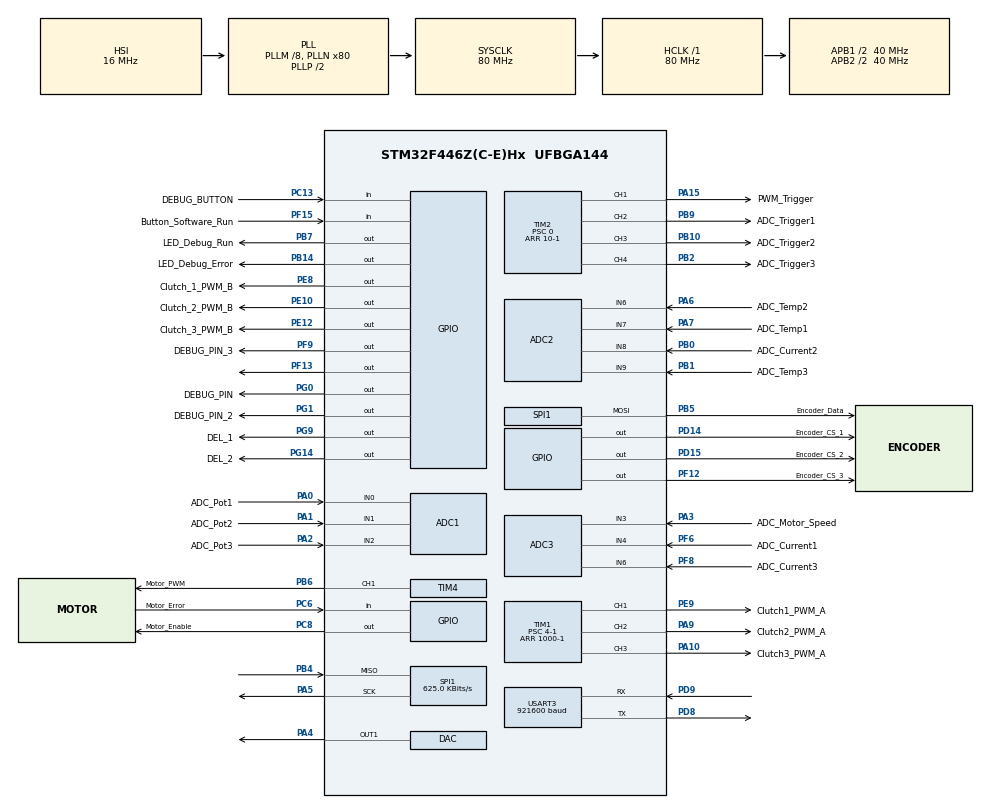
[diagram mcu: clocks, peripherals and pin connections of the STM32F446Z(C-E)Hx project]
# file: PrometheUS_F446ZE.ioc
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ADC1.Channel-0\#ChannelRegularConversion=ADC_CHANNEL_0
ADC1.Channel-1\#ChannelRegularConversion=ADC_CHANNEL_1
ADC1.Channel-2\#ChannelRegularConversion=ADC_CHANNEL_2
ADC1.ContinuousConvMode=DISABLE
ADC1.DMAContinuousRequests=ENABLE
ADC1.DiscontinuousConvMode=DISABLE
ADC1.EOCSelection=ADC_EOC_SEQ_CONV
ADC1.EnableAnalogWatchDog=false
ADC1.ExternalTrigConv=ADC_EXTERNALTRIGCONV_T2_CC2
ADC1.ExternalTrigConvEdge=ADC_EXTERNALTRIGCONVEDGE_RISINGFALLING
ADC1.InjNumberOfConversion=0
ADC1.NbrOfConversion=3
ADC1.NbrOfConversionFlag=1
ADC1.Rank-0\#ChannelRegularConversion=1
ADC1.Rank-1\#ChannelRegularConversion=2
ADC1.Rank-2\#ChannelRegularConversion=3
ADC1.SamplingTime-0\#ChannelRegularConversion=ADC_SAMPLETIME_3CYCLES
ADC1.SamplingTime-1\#ChannelRegularConversion=ADC_SAMPLETIME_3CYCLES
ADC1.SamplingTime-2\#ChannelRegularConversion=ADC_SAMPLETIME_3CYCLES
ADC1.ScanConvMode=ENABLE
ADC1.master=1
ADC2.Channel-4\#ChannelRegularConversion=ADC_CHANNEL_7
ADC2.Channel-5\#ChannelRegularConversion=ADC_CHANNEL_6
ADC2.Channel-6\#ChannelRegularConversion=ADC_CHANNEL_9
ADC2.Channel-7\#ChannelInjectedConversion=ADC_CHANNEL_8
ADC2.DMAContinuousRequests=ENABLE
ADC2.EOCSelection=ADC_EOC_SEQ_CONV
ADC2.ExternalTrigConv=ADC_EXTERNALTRIGCONV_T2_CC2
ADC2.ExternalTrigConvEdge=ADC_EXTERNALTRIGCONVEDGE_RISINGFALLING
ADC2.InjNumberOfConversion=1
ADC2.InjectedOffset-7\#ChannelInjectedConversion=0
ADC2.InjectedRank-7\#ChannelInjectedConversion=1
ADC2.NbrOfConversion=3
ADC2.NbrOfConversionFlag=1
ADC2.Rank-4\#ChannelRegularConversion=1
ADC2.Rank-5\#ChannelRegularConversion=2
ADC2.Rank-6\#ChannelRegularConversion=3
ADC2.SamplingTime-4\#ChannelRegularConversion=ADC_SAMPLETIME_3CYCLES
ADC2.SamplingTime-5\#ChannelRegularConversion=ADC_SAMPLETIME_3CYCLES
ADC2.SamplingTime-6\#ChannelRegularConversion=ADC_SAMPLETIME_3CYCLES
ADC2.SamplingTime-7\#ChannelInjectedConversion=ADC_SAMPLETIME_3CYCLES
ADC2.ScanConvMode=ENABLE
ADC3.Channel-0\#ChannelRegularConversion=ADC_CHANNEL_3
ADC3.NbrOfConversionFlag=1
ADC3.Rank-0\#ChannelRegularConversion=1
ADC3.SamplingTime-0\#ChannelRegularConversion=ADC_SAMPLETIME_3CYCLES
DAC.DAC_Trigger=DAC_TRIGGER_NONE
Dma.ADC1.0.Direction=DMA_PERIPH_TO_MEMORY
Dma.ADC1.0.FIFOMode=DMA_FIFOMODE_DISABLE
Dma.ADC1.0.Instance=DMA2_Stream0
Dma.ADC1.0.MemDataAlignment=DMA_MDATAALIGN_HALFWORD
Dma.ADC1.0.MemInc=DMA_MINC_ENABLE
Dma.ADC1.0.Mode=DMA_CIRCULAR
Dma.ADC1.0.PeriphDataAlignment=DMA_PDATAALIGN_HALFWORD
Dma.ADC1.0.PeriphInc=DMA_PINC_DISABLE
Dma.ADC1.0.Priority=DMA_PRIORITY_HIGH
Dma.ADC2.1.Direction=DMA_PERIPH_TO_MEMORY
Dma.ADC2.1.FIFOMode=DMA_FIFOMODE_DISABLE
Dma.ADC2.1.Instance=DMA2_Stream2
Dma.ADC2.1.MemDataAlignment=DMA_MDATAALIGN_HALFWORD
Dma.ADC2.1.MemInc=DMA_MINC_ENABLE
Dma.ADC2.1.Mode=DMA_CIRCULAR
Dma.ADC2.1.PeriphDataAlignment=DMA_PDATAALIGN_HALFWORD
Dma.ADC2.1.PeriphInc=DMA_PINC_DISABLE
Dma.ADC2.1.Priority=DMA_PRIORITY_HIGH
Dma.ADC3.2.Direction=DMA_PERIPH_TO_MEMORY
Dma.ADC3.2.FIFOMode=DMA_FIFOMODE_DISABLE
Dma.ADC3.2.Instance=DMA2_Stream1
Dma.ADC3.2.MemDataAlignment=DMA_MDATAALIGN_HALFWORD
Dma.ADC3.2.MemInc=DMA_MINC_ENABLE
Dma.ADC3.2.Mode=DMA_NORMAL
Dma.ADC3.2.PeriphDataAlignment=DMA_PDATAALIGN_HALFWORD
Dma.ADC3.2.PeriphInc=DMA_PINC_DISABLE
Dma.ADC3.2.Priority=DMA_PRIORITY_VERY_HIGH
Dma.Request0=ADC1
Dma.Request1=ADC2
Dma.Request2=ADC3
Dma.Request3=USART3_TX
Dma.USART3_TX.3.Direction=DMA_MEMORY_TO_PERIPH
Dma.USART3_TX.3.FIFOMode=DMA_FIFOMODE_DISABLE
Dma.USART3_TX.3.Instance=DMA1_Stream3
Dma.USART3_TX.3.MemDataAlignment=DMA_MDATAALIGN_BYTE
Dma.USART3_TX.3.MemInc=DMA_MINC_ENABLE
Dma.USART3_TX.3.Mode=DMA_NORMAL
Dma.USART3_TX.3.PeriphDataAlignment=DMA_PDATAALIGN_BYTE
Dma.USART3_TX.3.PeriphInc=DMA_PINC_DISABLE
Dma.USART3_TX.3.Priority=DMA_PRIORITY_MEDIUM
Mcu.Family=STM32F4
Mcu.Name=STM32F446Z(C-E)Hx
Mcu.Package=UFBGA144
NVIC.ADC_IRQn=true\:0\:0\:false\:false\:true\:true\:true\:true
NVIC.DMA1_Stream3_IRQn=true\:0\:0\:false\:false\:true\:false\:true\:true
NVIC.DMA2_Stream0_IRQn=true\:0\:0\:false\:false\:true\:false\:true\:true
NVIC.DMA2_Stream1_IRQn=true\:0\:0\:false\:false\:true\:false\:true\:true
NVIC.DMA2_Stream2_IRQn=true\:0\:0\:false\:false\:true\:false\:true\:true
NVIC.PriorityGroup=NVIC_PRIORITYGROUP_4
NVIC.TIM2_IRQn=true\:0\:0\:false\:false\:true\:true\:true\:true
NVIC.USART3_IRQn=true\:0\:0\:false\:false\:true\:true\:true\:true
PA0-WKUP.GPIO_Label=ADC_Pot1
PA0-WKUP.Signal=ADCx_IN0
PA1.GPIO_Label=ADC_Pot2
PA1.Signal=ADCx_IN1
PA10.GPIO_Label=Clutch3_PWM_A
PA10.Signal=S_TIM1_CH3
PA15.GPIO_Label=PWM_Trigger
PA15.Signal=S_TIM2_CH1_ETR
PA2.GPIO_Label=ADC_Pot3
PA2.Signal=ADCx_IN2
PA3.GPIO_Label=ADC_Motor_Speed
PA3.Signal=ADCx_IN3
PA4.Signal=COMP_DAC1_group
PA5.Mode=Full_Duplex_Master
PA5.Signal=SPI1_SCK
PA6.GPIO_Label=ADC_Temp2
PA6.Signal=ADCx_IN6
PA7.GPIO_Label=ADC_Temp1
PA7.Signal=ADCx_IN7
PA9.GPIO_Label=Clutch2_PWM_A
PA9.Signal=S_TIM1_CH2
PB0.GPIO_Label=ADC_Current2
PB0.Signal=ADCx_IN8
PB1.GPIO_Label=ADC_Temp3
PB1.Signal=ADCx_IN9
PB10.GPIO_Label=ADC_Trigger2
PB10.Signal=S_TIM2_CH3
PB14.GPIO_Label=LED_Debug_Error
PB14.Signal=GPIO_Output
PB2.GPIO_Label=ADC_Trigger3
PB2.Signal=S_TIM2_CH4
PB4.Mode=Full_Duplex_Master
PB4.Signal=SPI1_MISO
PB5.GPIO_Label=Encoder_Data
PB5.Mode=Full_Duplex_Master
PB5.Signal=SPI1_MOSI
PB6.GPIO_Label=Motor_PWM
PB6.Signal=S_TIM4_CH1
PB7.GPIO_Label=LED_Debug_Run
PB7.Signal=GPIO_Output
PB9.GPIO_Label=ADC_Trigger1
PB9.Signal=S_TIM2_CH2
PC13.GPIO_Label=DEBUG_BUTTON
PC13.GPIO_PuPd=GPIO_PULLDOWN
PC13.Signal=GPIO_Input
PC6.GPIO_Label=Motor_Error
PC6.Signal=GPIO_Input
PC8.GPIO_Label=Motor_Enable
PC8.Signal=GPIO_Output
PD14.GPIO_Label=Encoder_CS_1
PD14.Signal=GPIO_Output
PD15.GPIO_Label=Encoder_CS_2
PD15.Signal=GPIO_Output
PD8.Mode=Asynchronous
PD8.Signal=USART3_TX
PD9.Mode=Asynchronous
PD9.Signal=USART3_RX
PE10.GPIO_Label=Clutch_2_PWM_B
PE10.Signal=GPIO_Output
PE12.GPIO_Label=Clutch_3_PWM_B
PE12.Signal=GPIO_Output
PE8.GPIO_Label=Clutch_1_PWM_B
PE8.Signal=GPIO_Output
PE9.GPIO_Label=Clutch1_PWM_A
PE9.Signal=S_TIM1_CH1
PF12.GPIO_Label=Encoder_CS_3
PF12.Signal=GPIO_Output
PF13.Signal=GPIO_Output
PF15.GPIO_Label=Button_Software_Run
PF15.GPIO_PuPd=GPIO_PULLUP
PF15.Signal=GPIO_Input
PF6.GPIO_Label=ADC_Current1
PF6.Mode=IN4
PF6.Signal=ADC3_IN4
PF8.GPIO_Label=ADC_Current3
PF8.Mode=IN6
PF8.Signal=ADC3_IN6
PF9.GPIO_Label=DEBUG_PIN_3
PF9.Signal=GPIO_Output
PG0.GPIO_Label=DEBUG_PIN
PG0.Signal=GPIO_Output
PG1.GPIO_Label=DEBUG_PIN_2
PG1.Signal=GPIO_Output
PG14.GPIO_Label=DEL_2
PG14.Signal=GPIO_Output
PG9.GPIO_Label=DEL_1
PG9.Signal=GPIO_Output
ProjectManager.HeapSize=0x200
ProjectManager.StackSize=0x400
ProjectManager.TargetToolchain=STM32CubeIDE
RCC.AHBFreq_Value=80000000
RCC.APB1CLKDivider=RCC_HCLK_DIV2
RCC.APB1Freq_Value=40000000
RCC.APB1TimFreq_Value=80000000
RCC.APB2CLKDivider=RCC_HCLK_DIV2
RCC.APB2Freq_Value=40000000
RCC.APB2TimFreq_Value=80000000
RCC.CortexFreq_Value=80000000
RCC.HCLKFreq_Value=80000000
RCC.PLLM=8
RCC.PLLN=80
RCC.SYSCLKFreq_VALUE=80000000
RCC.SYSCLKSource=RCC_SYSCLKSOURCE_PLLCLK
RCC.USBFreq_Value=80000000
RCC.VCOOutputFreq_Value=160000000
SH.ADCx_IN0.0=ADC1_IN0,IN0
SH.ADCx_IN1.0=ADC1_IN1,IN1
SH.ADCx_IN2.0=ADC1_IN2,IN2
SH.ADCx_IN3.0=ADC3_IN3,IN3
SH.ADCx_IN6.0=ADC2_IN6,IN6
SH.ADCx_IN7.0=ADC2_IN7,IN7
SH.ADCx_IN8.0=ADC2_IN8,IN8
SH.ADCx_IN9.0=ADC2_IN9,IN9
SH.COMP_DAC1_group.0=DAC_OUT1,DAC_OUT1
SH.S_TIM1_CH1.0=TIM1_CH1,PWM Generation1 CH1
SH.S_TIM1_CH2.0=TIM1_CH2,PWM Generation2 CH2
SH.S_TIM1_CH3.0=TIM1_CH3,PWM Generation3 CH3
SH.S_TIM2_CH1_ETR.0=TIM2_CH1,Output Compare1 CH1
SH.S_TIM2_CH2.0=TIM2_CH2,Output Compare2 CH2
SH.S_TIM2_CH3.0=TIM2_CH3,Output Compare3 CH3
SH.S_TIM2_CH4.0=TIM2_CH4,Output Compare4 CH4
SH.S_TIM4_CH1.0=TIM4_CH1,PWM Generation1 CH1
SPI1.BaudRatePrescaler=SPI_BAUDRATEPRESCALER_64
SPI1.CalculateBaudRate=625.0 KBits/s
SPI1.DataSize=SPI_DATASIZE_16BIT
SPI1.Direction=SPI_DIRECTION_2LINES
SPI1.Mode=SPI_MODE_MASTER
SPI1.VirtualType=VM_MASTER
TIM1.Channel-PWM\ Generation1\ CH1=TIM_CHANNEL_1
TIM1.Channel-PWM\ Generation2\ CH2=TIM_CHANNEL_2
TIM1.Channel-PWM\ Generation3\ CH3=TIM_CHANNEL_3
TIM1.CounterMode=TIM_COUNTERMODE_CENTERALIGNED1
TIM1.OCPolarity_2=TIM_OCPOLARITY_HIGH
TIM1.OCPolarity_3=TIM_OCPOLARITY_HIGH
TIM1.OffStateIDLEMode=TIM_OSSI_ENABLE
TIM1.OffStateRunMode=TIM_OSSR_ENABLE
TIM1.Period=1000-1
TIM1.Prescaler=4-1
TIM1.TIM_MasterOutputTrigger=TIM_TRGO_UPDATE
TIM2.Channel-Output\ Compare1\ CH1=TIM_CHANNEL_1
TIM2.Channel-Output\ Compare2\ CH2=TIM_CHANNEL_2
TIM2.Channel-Output\ Compare3\ CH3=TIM_CHANNEL_3
TIM2.Channel-Output\ Compare4\ CH4=TIM_CHANNEL_4
TIM2.CounterMode=TIM_COUNTERMODE_UP
TIM2.OCMode_1=TIM_OCMODE_TOGGLE
TIM2.OCMode_2=TIM_OCMODE_TOGGLE
TIM2.OCMode_3=TIM_OCMODE_TOGGLE
TIM2.OCMode_4=TIM_OCMODE_TOGGLE
TIM2.Period=10-1
TIM2.Prescaler=0
TIM2.Pulse-Output\ Compare1\ CH1=9
TIM2.Pulse-Output\ Compare3\ CH3=1
TIM2.Pulse-Output\ Compare4\ CH4=2
TIM3.AutoReloadPreload=TIM_AUTORELOAD_PRELOAD_DISABLE
TIM3.Channel-Output\ Compare1\ No\ Output=TIM_CHANNEL_1
TIM3.CounterMode=TIM_COUNTERMODE_CENTERALIGNED1
TIM3.OCMode_1=TIM_OCMODE_TOGGLE
TIM3.OCPolarity_1=TIM_OCPOLARITY_HIGH
TIM3.Period=1000-1
TIM3.Prescaler=4-1
TIM3.Pulse-Output\ Compare1\ No\ Output=10
TIM3.TIM_MasterOutputTrigger=TIM_TRGO_OC1REF
TIM4.Channel-PWM\ Generation1\ CH1=TIM_CHANNEL_1
TIM4.CounterMode=TIM_COUNTERMODE_CENTERALIGNED1
TIM4.OCPolarity_1=TIM_OCPOLARITY_HIGH
TIM4.Period=1000-1
TIM4.Prescaler=4-1
TIM4.Pulse-PWM\ Generation1\ CH1=0
USART3.BaudRate=921600
USART3.VirtualMode=VM_ASYNC
VP_TIM2_VS_ClockSourceITR.Mode=TriggerSource_ITR2
VP_TIM2_VS_ControllerModeClock.Mode=Clock Mode
VP_TIM3_VS_ClockSourceITR.Mode=TriggerSource_ITR0
VP_TIM3_VS_ControllerModeTrigger.Mode=Trigger Mode
VP_TIM3_VS_no_output1.Mode=Output Compare1 No Output
board=custom

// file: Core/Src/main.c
/* USER CODE BEGIN Header */
/**
  ******************************************************************************
  * @file           : main.c
  * @brief          : Main program body
  ******************************************************************************
  * @attention
  *
  * Copyright (c) 2025 STMicroelectronics.
  * All rights reserved.
  *
  * This software is licensed under terms that can be found in the LICENSE file
  * in the root directory of this software component.
  * If no LICENSE file comes with this software, it is provided AS-IS.
  *
  ******************************************************************************
  */
/* USER CODE END Header */
#include "main.h"

/* USER CODE BEGIN Includes */
#include "cppMain.hpp"
/* USER CODE END Includes */

ADC_HandleTypeDef hadc1;
ADC_HandleTypeDef hadc2;
ADC_HandleTypeDef hadc3;
DMA_HandleTypeDef hdma_adc1;
DMA_HandleTypeDef hdma_adc2;
DMA_HandleTypeDef hdma_adc3;

DAC_HandleTypeDef hdac;

SPI_HandleTypeDef hspi1;

TIM_HandleTypeDef htim1;
TIM_HandleTypeDef htim2;
TIM_HandleTypeDef htim3;
TIM_HandleTypeDef htim4;

UART_HandleTypeDef huart3;
DMA_HandleTypeDef hdma_usart3_tx;

void SystemClock_Config(void);
static void MX_GPIO_Init(void);
static void MX_DMA_Init(void);
static void MX_TIM1_Init(void);
static void MX_SPI1_Init(void);
static void MX_TIM3_Init(void);
static void MX_TIM4_Init(void);
static void MX_TIM2_Init(void);
static void MX_ADC1_Init(void);
static void MX_ADC2_Init(void);
static void MX_ADC3_Init(void);
static void MX_DAC_Init(void);
static void MX_USART3_UART_Init(void);

int main(void)
{

  /* MCU Configuration--------------------------------------------------------*/

  /* Reset of all peripherals, Initializes the Flash interface and the Systick. */
  HAL_Init();

  /* Configure the system clock */
  SystemClock_Config();

  /* Initialize all configured peripherals */
  MX_GPIO_Init();
  MX_DMA_Init();
  MX_TIM1_Init();
  MX_SPI1_Init();
  MX_TIM3_Init();
  MX_TIM4_Init();
  MX_TIM2_Init();
  MX_ADC1_Init();
  MX_ADC2_Init();
  MX_ADC3_Init();
  MX_DAC_Init();
  MX_USART3_UART_Init();
  /* USER CODE BEGIN 2 */
  cppMain();
  /* USER CODE END 2 */

  /* Infinite loop */
  while (1)
  {

  }
}

void SystemClock_Config(void)
{
  RCC_OscInitTypeDef RCC_OscInitStruct = {0};
  RCC_ClkInitTypeDef RCC_ClkInitStruct = {0};

  /** Configure the main internal regulator output voltage
  */
  __HAL_RCC_PWR_CLK_ENABLE();
  __HAL_PWR_VOLTAGESCALING_CONFIG(PWR_REGULATOR_VOLTAGE_SCALE3);

  /** Initializes the RCC Oscillators according to the specified parameters
  * in the RCC_OscInitTypeDef structure.
  */
  RCC_OscInitStruct.OscillatorType = RCC_OSCILLATORTYPE_HSI;
  RCC_OscInitStruct.HSIState = RCC_HSI_ON;
  RCC_OscInitStruct.HSICalibrationValue = RCC_HSICALIBRATION_DEFAULT;
  RCC_OscInitStruct.PLL.PLLState = RCC_PLL_ON;
  RCC_OscInitStruct.PLL.PLLSource = RCC_PLLSOURCE_HSI;
  RCC_OscInitStruct.PLL.PLLM = 8;
  RCC_OscInitStruct.PLL.PLLN = 80;
  RCC_OscInitStruct.PLL.PLLP = RCC_PLLP_DIV2;
  RCC_OscInitStruct.PLL.PLLQ = 2;
  RCC_OscInitStruct.PLL.PLLR = 2;
  if (HAL_RCC_OscConfig(&RCC_OscInitStruct) != HAL_OK)
  {
    Error_Handler();
  }

  /** Initializes the CPU, AHB and APB buses clocks
  */
  RCC_ClkInitStruct.ClockType = RCC_CLOCKTYPE_HCLK|RCC_CLOCKTYPE_SYSCLK
                              |RCC_CLOCKTYPE_PCLK1|RCC_CLOCKTYPE_PCLK2;
  RCC_ClkInitStruct.SYSCLKSource = RCC_SYSCLKSOURCE_PLLCLK;
  RCC_ClkInitStruct.AHBCLKDivider = RCC_SYSCLK_DIV1;
  RCC_ClkInitStruct.APB1CLKDivider = RCC_HCLK_DIV2;
  RCC_ClkInitStruct.APB2CLKDivider = RCC_HCLK_DIV2;

  if (HAL_RCC_ClockConfig(&RCC_ClkInitStruct, FLASH_LATENCY_2) != HAL_OK)
  {
    Error_Handler();
  }
}

static void MX_ADC1_Init(void)
{

  ADC_ChannelConfTypeDef sConfig = {0};

  /** Configure the global features of the ADC (Clock, Resolution, Data Alignment and number of conversion)
  */
  hadc1.Instance = ADC1;
  hadc1.Init.ClockPrescaler = ADC_CLOCK_SYNC_PCLK_DIV2;
  hadc1.Init.Resolution = ADC_RESOLUTION_12B;
  hadc1.Init.ScanConvMode = ENABLE;
  hadc1.Init.ContinuousConvMode = DISABLE;
  hadc1.Init.DiscontinuousConvMode = DISABLE;
  hadc1.Init.ExternalTrigConvEdge = ADC_EXTERNALTRIGCONVEDGE_RISINGFALLING;
  hadc1.Init.ExternalTrigConv = ADC_EXTERNALTRIGCONV_T2_CC2;
  hadc1.Init.DataAlign = ADC_DATAALIGN_RIGHT;
  hadc1.Init.NbrOfConversion = 3;
  hadc1.Init.DMAContinuousRequests = ENABLE;
  hadc1.Init.EOCSelection = ADC_EOC_SEQ_CONV;
  if (HAL_ADC_Init(&hadc1) != HAL_OK)
  {
    Error_Handler();
  }

  /** Configure for the selected ADC regular channel its corresponding rank in the sequencer and its sample time.
  */
  sConfig.Channel = ADC_CHANNEL_0;
  sConfig.Rank = 1;
  sConfig.SamplingTime = ADC_SAMPLETIME_3CYCLES;
  if (HAL_ADC_ConfigChannel(&hadc1, &sConfig) != HAL_OK)
  {
    Error_Handler();
  }

  /** Configure for the selected ADC regular channel its corresponding rank in the sequencer and its sample time.
  */
  sConfig.Channel = ADC_CHANNEL_1;
  sConfig.Rank = 2;
  if (HAL_ADC_ConfigChannel(&hadc1, &sConfig) != HAL_OK)
  {
    Error_Handler();
  }

  /** Configure for the selected ADC regular channel its corresponding rank in the sequencer and its sample time.
  */
  sConfig.Channel = ADC_CHANNEL_2;
  sConfig.Rank = 3;
  if (HAL_ADC_ConfigChannel(&hadc1, &sConfig) != HAL_OK)
  {
    Error_Handler();
  }

}

static void MX_ADC2_Init(void)
{

  ADC_ChannelConfTypeDef sConfig = {0};
  ADC_InjectionConfTypeDef sConfigInjected = {0};

  /** Configure the global features of the ADC (Clock, Resolution, Data Alignment and number of conversion)
  */
  hadc2.Instance = ADC2;
  hadc2.Init.ClockPrescaler = ADC_CLOCK_SYNC_PCLK_DIV2;
  hadc2.Init.Resolution = ADC_RESOLUTION_12B;
  hadc2.Init.ScanConvMode = ENABLE;
  hadc2.Init.ContinuousConvMode = DISABLE;
  hadc2.Init.DiscontinuousConvMode = DISABLE;
  hadc2.Init.ExternalTrigConvEdge = ADC_EXTERNALTRIGCONVEDGE_RISINGFALLING;
  hadc2.Init.ExternalTrigConv = ADC_EXTERNALTRIGCONV_T2_CC2;
  hadc2.Init.DataAlign = ADC_DATAALIGN_RIGHT;
  hadc2.Init.NbrOfConversion = 3;
  hadc2.Init.DMAContinuousRequests = ENABLE;
  hadc2.Init.EOCSelection = ADC_EOC_SEQ_CONV;
  if (HAL_ADC_Init(&hadc2) != HAL_OK)
  {
    Error_Handler();
  }

  /** Configure for the selected ADC regular channel its corresponding rank in the sequencer and its sample time.
  */
  sConfig.Channel = ADC_CHANNEL_7;
  sConfig.Rank = 1;
  sConfig.SamplingTime = ADC_SAMPLETIME_3CYCLES;
  if (HAL_ADC_ConfigChannel(&hadc2, &sConfig) != HAL_OK)
  {
    Error_Handler();
  }

  /** Configure for the selected ADC regular channel its corresponding rank in the sequencer and its sample time.
  */
  sConfig.Channel = ADC_CHANNEL_6;
  sConfig.Rank = 2;
  if (HAL_ADC_ConfigChannel(&hadc2, &sConfig) != HAL_OK)
  {
    Error_Handler();
  }

  /** Configure for the selected ADC regular channel its corresponding rank in the sequencer and its sample time.
  */
  sConfig.Channel = ADC_CHANNEL_9;
  sConfig.Rank = 3;
  if (HAL_ADC_ConfigChannel(&hadc2, &sConfig) != HAL_OK)
  {
    Error_Handler();
  }

  /** Configures for the selected ADC injected channel its corresponding rank in the sequencer and its sample time
  */
  sConfigInjected.InjectedChannel = ADC_CHANNEL_8;
  sConfigInjected.InjectedRank = 1;
  sConfigInjected.InjectedNbrOfConversion = 1;
  sConfigInjected.InjectedSamplingTime = ADC_SAMPLETIME_3CYCLES;
  sConfigInjected.ExternalTrigInjecConvEdge = ADC_EXTERNALTRIGINJECCONVEDGE_NONE;
  sConfigInjected.ExternalTrigInjecConv = ADC_INJECTED_SOFTWARE_START;
  sConfigInjected.AutoInjectedConv = DISABLE;
  sConfigInjected.InjectedDiscontinuousConvMode = DISABLE;
  sConfigInjected.InjectedOffset = 0;
  if (HAL_ADCEx_InjectedConfigChannel(&hadc2, &sConfigInjected) != HAL_OK)
  {
    Error_Handler();
  }

}

static void MX_ADC3_Init(void)
{

  ADC_ChannelConfTypeDef sConfig = {0};

  /** Configure the global features of the ADC (Clock, Resolution, Data Alignment and number of conversion)
  */
  hadc3.Instance = ADC3;
  hadc3.Init.ClockPrescaler = ADC_CLOCK_SYNC_PCLK_DIV2;
  hadc3.Init.Resolution = ADC_RESOLUTION_12B;
  hadc3.Init.ScanConvMode = DISABLE;
  hadc3.Init.ContinuousConvMode = DISABLE;
  hadc3.Init.DiscontinuousConvMode = DISABLE;
  hadc3.Init.ExternalTrigConvEdge = ADC_EXTERNALTRIGCONVEDGE_NONE;
  hadc3.Init.ExternalTrigConv = ADC_SOFTWARE_START;
  hadc3.Init.DataAlign = ADC_DATAALIGN_RIGHT;
  hadc3.Init.NbrOfConversion = 1;
  hadc3.Init.DMAContinuousRequests = DISABLE;
  hadc3.Init.EOCSelection = ADC_EOC_SINGLE_CONV;
  if (HAL_ADC_Init(&hadc3) != HAL_OK)
  {
    Error_Handler();
  }

  /** Configure for the selected ADC regular channel its corresponding rank in the sequencer and its sample time.
  */
  sConfig.Channel = ADC_CHANNEL_3;
  sConfig.Rank = 1;
  sConfig.SamplingTime = ADC_SAMPLETIME_3CYCLES;
  if (HAL_ADC_ConfigChannel(&hadc3, &sConfig) != HAL_OK)
  {
    Error_Handler();
  }

}

static void MX_DAC_Init(void)
{

  DAC_ChannelConfTypeDef sConfig = {0};

  /** DAC Initialization
  */
  hdac.Instance = DAC;
  if (HAL_DAC_Init(&hdac) != HAL_OK)
  {
    Error_Handler();
  }

  /** DAC channel OUT1 config
  */
  sConfig.DAC_Trigger = DAC_TRIGGER_NONE;
  sConfig.DAC_OutputBuffer = DAC_OUTPUTBUFFER_ENABLE;
  if (HAL_DAC_ConfigChannel(&hdac, &sConfig, DAC_CHANNEL_1) != HAL_OK)
  {
    Error_Handler();
  }

}

static void MX_SPI1_Init(void)
{

  /* SPI1 parameter configuration*/
  hspi1.Instance = SPI1;
  hspi1.Init.Mode = SPI_MODE_MASTER;
  hspi1.Init.Direction = SPI_DIRECTION_2LINES;
  hspi1.Init.DataSize = SPI_DATASIZE_16BIT;
  hspi1.Init.CLKPolarity = SPI_POLARITY_LOW;
  hspi1.Init.CLKPhase = SPI_PHASE_1EDGE;
  hspi1.Init.NSS = SPI_NSS_SOFT;
  hspi1.Init.BaudRatePrescaler = SPI_BAUDRATEPRESCALER_64;
  hspi1.Init.FirstBit = SPI_FIRSTBIT_MSB;
  hspi1.Init.TIMode = SPI_TIMODE_DISABLE;
  hspi1.Init.CRCCalculation = SPI_CRCCALCULATION_DISABLE;
  hspi1.Init.CRCPolynomial = 10;
  if (HAL_SPI_Init(&hspi1) != HAL_OK)
  {
    Error_Handler();
  }

}

static void MX_TIM1_Init(void)
{

  TIM_MasterConfigTypeDef sMasterConfig = {0};
  TIM_OC_InitTypeDef sConfigOC = {0};
  TIM_BreakDeadTimeConfigTypeDef sBreakDeadTimeConfig = {0};

  htim1.Instance = TIM1;
  htim1.Init.Prescaler = 4-1;
  htim1.Init.CounterMode = TIM_COUNTERMODE_CENTERALIGNED1;
  htim1.Init.Period = 1000-1;
  htim1.Init.ClockDivision = TIM_CLOCKDIVISION_DIV1;
  htim1.Init.RepetitionCounter = 0;
  htim1.Init.AutoReloadPreload = TIM_AUTORELOAD_PRELOAD_DISABLE;
  if (HAL_TIM_PWM_Init(&htim1) != HAL_OK)
  {
    Error_Handler();
  }
  sMasterConfig.MasterOutputTrigger = TIM_TRGO_UPDATE;
  sMasterConfig.MasterSlaveMode = TIM_MASTERSLAVEMODE_DISABLE;
  if (HAL_TIMEx_MasterConfigSynchronization(&htim1, &sMasterConfig) != HAL_OK)
  {
    Error_Handler();
  }
  sConfigOC.OCMode = TIM_OCMODE_PWM1;
  sConfigOC.Pulse = 0;
  sConfigOC.OCPolarity = TIM_OCPOLARITY_HIGH;
  sConfigOC.OCNPolarity = TIM_OCNPOLARITY_HIGH;
  sConfigOC.OCFastMode = TIM_OCFAST_DISABLE;
  sConfigOC.OCIdleState = TIM_OCIDLESTATE_RESET;
  sConfigOC.OCNIdleState = TIM_OCNIDLESTATE_RESET;
  if (HAL_TIM_PWM_ConfigChannel(&htim1, &sConfigOC, TIM_CHANNEL_1) != HAL_OK)
  {
    Error_Handler();
  }
  if (HAL_TIM_PWM_ConfigChannel(&htim1, &sConfigOC, TIM_CHANNEL_2) != HAL_OK)
  {
    Error_Handler();
  }
  if (HAL_TIM_PWM_ConfigChannel(&htim1, &sConfigOC, TIM_CHANNEL_3) != HAL_OK)
  {
    Error_Handler();
  }
  sBreakDeadTimeConfig.OffStateRunMode = TIM_OSSR_ENABLE;
  sBreakDeadTimeConfig.OffStateIDLEMode = TIM_OSSI_ENABLE;
  sBreakDeadTimeConfig.LockLevel = TIM_LOCKLEVEL_OFF;
  sBreakDeadTimeConfig.DeadTime = 0;
  sBreakDeadTimeConfig.BreakState = TIM_BREAK_DISABLE;
  sBreakDeadTimeConfig.BreakPolarity = TIM_BREAKPOLARITY_HIGH;
  sBreakDeadTimeConfig.AutomaticOutput = TIM_AUTOMATICOUTPUT_DISABLE;
  if (HAL_TIMEx_ConfigBreakDeadTime(&htim1, &sBreakDeadTimeConfig) != HAL_OK)
  {
    Error_Handler();
  }
  HAL_TIM_MspPostInit(&htim1);

}

static void MX_TIM2_Init(void)
{

  TIM_SlaveConfigTypeDef sSlaveConfig = {0};
  TIM_MasterConfigTypeDef sMasterConfig = {0};
  TIM_OC_InitTypeDef sConfigOC = {0};

  htim2.Instance = TIM2;
  htim2.Init.Prescaler = 0;
  htim2.Init.CounterMode = TIM_COUNTERMODE_UP;
  htim2.Init.Period = 10-1;
  htim2.Init.ClockDivision = TIM_CLOCKDIVISION_DIV1;
  htim2.Init.AutoReloadPreload = TIM_AUTORELOAD_PRELOAD_DISABLE;
  if (HAL_TIM_Base_Init(&htim2) != HAL_OK)
  {
    Error_Handler();
  }
  if (HAL_TIM_OC_Init(&htim2) != HAL_OK)
  {
    Error_Handler();
  }
  sSlaveConfig.SlaveMode = TIM_SLAVEMODE_EXTERNAL1;
  sSlaveConfig.InputTrigger = TIM_TS_ITR2;
  if (HAL_TIM_SlaveConfigSynchro(&htim2, &sSlaveConfig) != HAL_OK)
  {
    Error_Handler();
  }
  sMasterConfig.MasterOutputTrigger = TIM_TRGO_RESET;
  sMasterConfig.MasterSlaveMode = TIM_MASTERSLAVEMODE_DISABLE;
  if (HAL_TIMEx_MasterConfigSynchronization(&htim2, &sMasterConfig) != HAL_OK)
  {
    Error_Handler();
  }
  sConfigOC.OCMode = TIM_OCMODE_TOGGLE;
  sConfigOC.Pulse = 9;
  sConfigOC.OCPolarity = TIM_OCPOLARITY_HIGH;
  sConfigOC.OCFastMode = TIM_OCFAST_DISABLE;
  if (HAL_TIM_OC_ConfigChannel(&htim2, &sConfigOC, TIM_CHANNEL_1) != HAL_OK)
  {
    Error_Handler();
  }
  sConfigOC.Pulse = 0;
  if (HAL_TIM_OC_ConfigChannel(&htim2, &sConfigOC, TIM_CHANNEL_2) != HAL_OK)
  {
    Error_Handler();
  }
  sConfigOC.Pulse = 1;
  if (HAL_TIM_OC_ConfigChannel(&htim2, &sConfigOC, TIM_CHANNEL_3) != HAL_OK)
  {
    Error_Handler();
  }
  sConfigOC.Pulse = 2;
  if (HAL_TIM_OC_ConfigChannel(&htim2, &sConfigOC, TIM_CHANNEL_4) != HAL_OK)
  {
    Error_Handler();
  }
  HAL_TIM_MspPostInit(&htim2);

}

static void MX_TIM3_Init(void)
{

  TIM_SlaveConfigTypeDef sSlaveConfig = {0};
  TIM_MasterConfigTypeDef sMasterConfig = {0};
  TIM_OC_InitTypeDef sConfigOC = {0};

  htim3.Instance = TIM3;
  htim3.Init.Prescaler = 4-1;
  htim3.Init.CounterMode = TIM_COUNTERMODE_CENTERALIGNED1;
  htim3.Init.Period = 1000-1;
  htim3.Init.ClockDivision = TIM_CLOCKDIVISION_DIV1;
  htim3.Init.AutoReloadPreload = TIM_AUTORELOAD_PRELOAD_DISABLE;
  if (HAL_TIM_Base_Init(&htim3) != HAL_OK)
  {
    Error_Handler();
  }
  if (HAL_TIM_OC_Init(&htim3) != HAL_OK)
  {
    Error_Handler();
  }
  sSlaveConfig.SlaveMode = TIM_SLAVEMODE_TRIGGER;
  sSlaveConfig.InputTrigger = TIM_TS_ITR0;
  if (HAL_TIM_SlaveConfigSynchro(&htim3, &sSlaveConfig) != HAL_OK)
  {
    Error_Handler();
  }
  sMasterConfig.MasterOutputTrigger = TIM_TRGO_OC1REF;
  sMasterConfig.MasterSlaveMode = TIM_MASTERSLAVEMODE_DISABLE;
  if (HAL_TIMEx_MasterConfigSynchronization(&htim3, &sMasterConfig) != HAL_OK)
  {
    Error_Handler();
  }
  sConfigOC.OCMode = TIM_OCMODE_TOGGLE;
  sConfigOC.Pulse = 10;
  sConfigOC.OCPolarity = TIM_OCPOLARITY_HIGH;
  sConfigOC.OCFastMode = TIM_OCFAST_DISABLE;
  if (HAL_TIM_OC_ConfigChannel(&htim3, &sConfigOC, TIM_CHANNEL_1) != HAL_OK)
  {
    Error_Handler();
  }

}

static void MX_TIM4_Init(void)
{

  TIM_MasterConfigTypeDef sMasterConfig = {0};
  TIM_OC_InitTypeDef sConfigOC = {0};

  htim4.Instance = TIM4;
  htim4.Init.Prescaler = 4-1;
  htim4.Init.CounterMode = TIM_COUNTERMODE_CENTERALIGNED1;
  htim4.Init.Period = 1000-1;
  htim4.Init.ClockDivision = TIM_CLOCKDIVISION_DIV1;
  htim4.Init.AutoReloadPreload = TIM_AUTORELOAD_PRELOAD_DISABLE;
  if (HAL_TIM_PWM_Init(&htim4) != HAL_OK)
  {
    Error_Handler();
  }
  sMasterConfig.MasterOutputTrigger = TIM_TRGO_RESET;
  sMasterConfig.MasterSlaveMode = TIM_MASTERSLAVEMODE_DISABLE;
  if (HAL_TIMEx_MasterConfigSynchronization(&htim4, &sMasterConfig) != HAL_OK)
  {
    Error_Handler();
  }
  sConfigOC.OCMode = TIM_OCMODE_PWM1;
  sConfigOC.Pulse = 0;
  sConfigOC.OCPolarity = TIM_OCPOLARITY_HIGH;
  sConfigOC.OCFastMode = TIM_OCFAST_DISABLE;
  if (HAL_TIM_PWM_ConfigChannel(&htim4, &sConfigOC, TIM_CHANNEL_1) != HAL_OK)
  {
    Error_Handler();
  }
  HAL_TIM_MspPostInit(&htim4);

}

static void MX_USART3_UART_Init(void)
{

  huart3.Instance = USART3;
  huart3.Init.BaudRate = 921600;
  huart3.Init.WordLength = UART_WORDLENGTH_8B;
  huart3.Init.StopBits = UART_STOPBITS_1;
  huart3.Init.Parity = UART_PARITY_NONE;
  huart3.Init.Mode = UART_MODE_TX_RX;
  huart3.Init.HwFlowCtl = UART_HWCONTROL_NONE;
  huart3.Init.OverSampling = UART_OVERSAMPLING_16;
  if (HAL_UART_Init(&huart3) != HAL_OK)
  {
    Error_Handler();
  }

}

static void MX_DMA_Init(void)
{

  /* DMA controller clock enable */
  __HAL_RCC_DMA2_CLK_ENABLE();
  __HAL_RCC_DMA1_CLK_ENABLE();

  /* DMA interrupt init */
  /* DMA1_Stream3_IRQn interrupt configuration */
  HAL_NVIC_SetPriority(DMA1_Stream3_IRQn, 0, 0);
  HAL_NVIC_EnableIRQ(DMA1_Stream3_IRQn);
  /* DMA2_Stream0_IRQn interrupt configuration */
  HAL_NVIC_SetPriority(DMA2_Stream0_IRQn, 0, 0);
  HAL_NVIC_EnableIRQ(DMA2_Stream0_IRQn);
  /* DMA2_Stream1_IRQn interrupt configuration */
  HAL_NVIC_SetPriority(DMA2_Stream1_IRQn, 0, 0);
  HAL_NVIC_EnableIRQ(DMA2_Stream1_IRQn);
  /* DMA2_Stream2_IRQn interrupt configuration */
  HAL_NVIC_SetPriority(DMA2_Stream2_IRQn, 0, 0);
  HAL_NVIC_EnableIRQ(DMA2_Stream2_IRQn);

}

static void MX_GPIO_Init(void)
{
  GPIO_InitTypeDef GPIO_InitStruct = {0};

  /* GPIO Ports Clock Enable */
  __HAL_RCC_GPIOC_CLK_ENABLE();
  __HAL_RCC_GPIOB_CLK_ENABLE();
  __HAL_RCC_GPIOA_CLK_ENABLE();
  __HAL_RCC_GPIOG_CLK_ENABLE();
  __HAL_RCC_GPIOF_CLK_ENABLE();
  __HAL_RCC_GPIOE_CLK_ENABLE();
  __HAL_RCC_GPIOD_CLK_ENABLE();

  /*Configure GPIO pin Output Level */
  HAL_GPIO_WritePin(GPIOG, DEL_2_Pin|DEL_1_Pin|DEBUG_PIN_2_Pin|DEBUG_PIN_Pin, GPIO_PIN_RESET);

  /*Configure GPIO pin Output Level */
  HAL_GPIO_WritePin(GPIOB, LED_Debug_Run_Pin|LED_Debug_Error_Pin, GPIO_PIN_RESET);

  /*Configure GPIO pin Output Level */
  HAL_GPIO_WritePin(Motor_Enable_GPIO_Port, Motor_Enable_Pin, GPIO_PIN_RESET);

  /*Configure GPIO pin Output Level */
  HAL_GPIO_WritePin(GPIOF, DEBUG_PIN_3_Pin|GPIO_PIN_13|Encoder_CS_3_Pin, GPIO_PIN_RESET);

  /*Configure GPIO pin Output Level */
  HAL_GPIO_WritePin(GPIOE, Clutch_2_PWM_B_Pin|Clutch_3_PWM_B_Pin|Clutch_1_PWM_B_Pin, GPIO_PIN_RESET);

  /*Configure GPIO pin Output Level */
  HAL_GPIO_WritePin(GPIOD, Encoder_CS_1_Pin|Encoder_CS_2_Pin, GPIO_PIN_RESET);

  /*Configure GPIO pin : DEBUG_BUTTON_Pin */
  GPIO_InitStruct.Pin = DEBUG_BUTTON_Pin;
  GPIO_InitStruct.Mode = GPIO_MODE_INPUT;
  GPIO_InitStruct.Pull = GPIO_PULLDOWN;
  HAL_GPIO_Init(DEBUG_BUTTON_GPIO_Port, &GPIO_InitStruct);

  /*Configure GPIO pins : DEL_2_Pin DEL_1_Pin DEBUG_PIN_2_Pin DEBUG_PIN_Pin */
  GPIO_InitStruct.Pin = DEL_2_Pin|DEL_1_Pin|DEBUG_PIN_2_Pin|DEBUG_PIN_Pin;
  GPIO_InitStruct.Mode = GPIO_MODE_OUTPUT_PP;
  GPIO_InitStruct.Pull = GPIO_NOPULL;
  GPIO_InitStruct.Speed = GPIO_SPEED_FREQ_LOW;
  HAL_GPIO_Init(GPIOG, &GPIO_InitStruct);

  /*Configure GPIO pins : LED_Debug_Run_Pin LED_Debug_Error_Pin */
  GPIO_InitStruct.Pin = LED_Debug_Run_Pin|LED_Debug_Error_Pin;
  GPIO_InitStruct.Mode = GPIO_MODE_OUTPUT_PP;
  GPIO_InitStruct.Pull = GPIO_NOPULL;
  GPIO_InitStruct.Speed = GPIO_SPEED_FREQ_LOW;
  HAL_GPIO_Init(GPIOB, &GPIO_InitStruct);

  /*Configure GPIO pin : Motor_Enable_Pin */
  GPIO_InitStruct.Pin = Motor_Enable_Pin;
  GPIO_InitStruct.Mode = GPIO_MODE_OUTPUT_PP;
  GPIO_InitStruct.Pull = GPIO_NOPULL;
  GPIO_InitStruct.Speed = GPIO_SPEED_FREQ_LOW;
  HAL_GPIO_Init(Motor_Enable_GPIO_Port, &GPIO_InitStruct);

  /*Configure GPIO pins : DEBUG_PIN_3_Pin PF13 Encoder_CS_3_Pin */
  GPIO_InitStruct.Pin = DEBUG_PIN_3_Pin|GPIO_PIN_13|Encoder_CS_3_Pin;
  GPIO_InitStruct.Mode = GPIO_MODE_OUTPUT_PP;
  GPIO_InitStruct.Pull = GPIO_NOPULL;
  GPIO_InitStruct.Speed = GPIO_SPEED_FREQ_LOW;
  HAL_GPIO_Init(GPIOF, &GPIO_InitStruct);

  /*Configure GPIO pin : Motor_Error_Pin */
  GPIO_InitStruct.Pin = Motor_Error_Pin;
  GPIO_InitStruct.Mode = GPIO_MODE_INPUT;
  GPIO_InitStruct.Pull = GPIO_NOPULL;
  HAL_GPIO_Init(Motor_Error_GPIO_Port, &GPIO_InitStruct);

  /*Configure GPIO pins : Clutch_2_PWM_B_Pin Clutch_3_PWM_B_Pin Clutch_1_PWM_B_Pin */
  GPIO_InitStruct.Pin = Clutch_2_PWM_B_Pin|Clutch_3_PWM_B_Pin|Clutch_1_PWM_B_Pin;
  GPIO_InitStruct.Mode = GPIO_MODE_OUTPUT_PP;
  GPIO_InitStruct.Pull = GPIO_NOPULL;
  GPIO_InitStruct.Speed = GPIO_SPEED_FREQ_LOW;
  HAL_GPIO_Init(GPIOE, &GPIO_InitStruct);

  /*Configure GPIO pins : Encoder_CS_1_Pin Encoder_CS_2_Pin */
  GPIO_InitStruct.Pin = Encoder_CS_1_Pin|Encoder_CS_2_Pin;
  GPIO_InitStruct.Mode = GPIO_MODE_OUTPUT_PP;
  GPIO_InitStruct.Pull = GPIO_NOPULL;
  GPIO_InitStruct.Speed = GPIO_SPEED_FREQ_LOW;
  HAL_GPIO_Init(GPIOD, &GPIO_InitStruct);

  /*Configure GPIO pin : Button_Software_Run_Pin */
  GPIO_InitStruct.Pin = Button_Software_Run_Pin;
  GPIO_InitStruct.Mode = GPIO_MODE_INPUT;
  GPIO_InitStruct.Pull = GPIO_PULLUP;
  HAL_GPIO_Init(Button_Software_Run_GPIO_Port, &GPIO_InitStruct);

}

void Error_Handler(void)
{
  __disable_irq();
  while (1)
  {
  }
}
